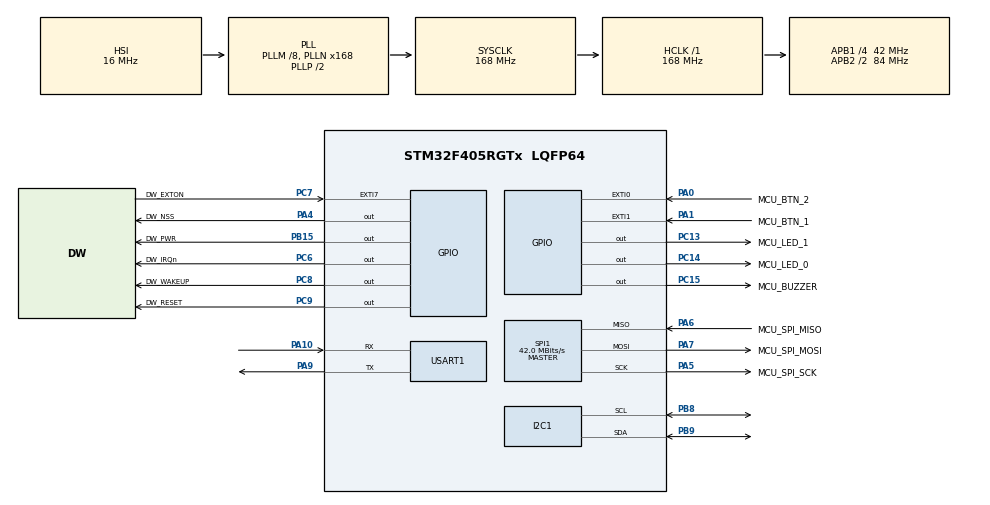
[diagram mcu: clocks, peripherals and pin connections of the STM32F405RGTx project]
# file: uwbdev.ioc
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I2C1.I2C_Mode=I2C_Fast
Mcu.Family=STM32F4
Mcu.Name=STM32F405RGTx
Mcu.Package=LQFP64
NVIC.EXTI0_IRQn=true\:0\:0\:false\:false\:true\:true\:true\:true
NVIC.EXTI1_IRQn=true\:0\:0\:false\:false\:true\:true\:true\:true
NVIC.EXTI9_5_IRQn=true\:0\:0\:false\:false\:true\:true\:true\:true
NVIC.PriorityGroup=NVIC_PRIORITYGROUP_4
PA0-WKUP.GPIO_Label=MCU_BTN_2
PA0-WKUP.GPIO_ModeDefaultEXTI=GPIO_MODE_IT_FALLING
PA0-WKUP.GPIO_PuPd=GPIO_PULLUP
PA0-WKUP.Signal=GPXTI0
PA1.GPIO_Label=MCU_BTN_1
PA1.GPIO_ModeDefaultEXTI=GPIO_MODE_IT_FALLING
PA1.GPIO_PuPd=GPIO_PULLUP
PA1.Signal=GPXTI1
PA10.Mode=Asynchronous
PA10.Signal=USART1_RX
PA13.Mode=Serial_Wire
PA13.Signal=SYS_JTMS-SWDIO
PA14.Mode=Serial_Wire
PA14.Signal=SYS_JTCK-SWCLK
PA4.GPIO_Label=DW_NSS
PA4.GPIO_Speed=GPIO_SPEED_FREQ_HIGH
PA4.Signal=GPIO_Output
PA5.GPIO_Label=MCU_SPI_SCK
PA5.Mode=Full_Duplex_Master
PA5.Signal=SPI1_SCK
PA6.GPIO_Label=MCU_SPI_MISO
PA6.Mode=Full_Duplex_Master
PA6.Signal=SPI1_MISO
PA7.GPIO_Label=MCU_SPI_MOSI
PA7.Mode=Full_Duplex_Master
PA7.Signal=SPI1_MOSI
PA9.Mode=Asynchronous
PA9.Signal=USART1_TX
PB15.GPIO_Label=DW_PWR
PB15.Signal=GPIO_Output
PB8.Mode=I2C
PB8.Signal=I2C1_SCL
PB9.Mode=I2C
PB9.Signal=I2C1_SDA
PC13-ANTI_TAMP.GPIO_Label=MCU_LED_1
PC13-ANTI_TAMP.Signal=GPIO_Output
PC14-OSC32_IN.GPIO_Label=MCU_LED_0
PC14-OSC32_IN.Signal=GPIO_Output
PC15-OSC32_OUT.GPIO_Label=MCU_BUZZER
PC15-OSC32_OUT.Signal=GPIO_Output
PC6.GPIO_Label=DW_IRQn
PC6.GPIO_Speed=GPIO_SPEED_FREQ_HIGH
PC6.PinState=GPIO_PIN_RESET
PC6.Signal=GPIO_Output
PC7.GPIO_Label=DW_EXTON
PC7.Signal=GPXTI7
PC8.GPIO_Label=DW_WAKEUP
PC8.GPIO_Speed=GPIO_SPEED_FREQ_HIGH
PC8.Signal=GPIO_Output
PC9.GPIO_Label=DW_RESET
PC9.GPIO_Speed=GPIO_SPEED_FREQ_HIGH
PC9.Signal=GPIO_Output
ProjectManager.HeapSize=0x200
ProjectManager.StackSize=0x400
ProjectManager.TargetToolchain=STM32CubeIDE
RCC.48MHZClocksFreq_Value=84000000
RCC.AHBFreq_Value=168000000
RCC.APB1CLKDivider=RCC_HCLK_DIV4
RCC.APB1Freq_Value=42000000
RCC.APB1TimFreq_Value=84000000
RCC.APB2CLKDivider=RCC_HCLK_DIV2
RCC.APB2Freq_Value=84000000
RCC.APB2TimFreq_Value=168000000
RCC.CortexFreq_Value=168000000
RCC.HCLKFreq_Value=168000000
RCC.HSE_VALUE=25000000
RCC.HSI_VALUE=16000000
RCC.LSE_VALUE=32768
RCC.PLLM=8
RCC.PLLN=168
RCC.SYSCLKFreq_VALUE=168000000
RCC.SYSCLKSource=RCC_SYSCLKSOURCE_PLLCLK
RCC.VCOOutputFreq_Value=336000000
SPI1.CalculateBaudRate=42.0 MBits/s
SPI1.Direction=SPI_DIRECTION_2LINES
SPI1.Mode=SPI_MODE_MASTER
SPI1.VirtualType=VM_MASTER
TIM5.Prescaler=167
USART1.VirtualMode=VM_ASYNC
VP_TIM5_VS_ClockSourceINT.Mode=Internal
board=custom

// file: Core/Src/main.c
/* USER CODE BEGIN Header */
/**
  ******************************************************************************
  * @file           : main.c
  * @brief          : Main program body
  ******************************************************************************
  * @attention
  *
  * Copyright (c) 2025 STMicroelectronics.
  * All rights reserved.
  *
  * This software is licensed under terms that can be found in the LICENSE file
  * in the root directory of this software component.
  * If no LICENSE file comes with this software, it is provided AS-IS.
  *
  ******************************************************************************
  */
/* USER CODE END Header */
#include "main.h"
#include "i2c.h"
#include "spi.h"
#include "tim.h"
#include "usart.h"
#include "gpio.h"

/* USER CODE BEGIN Includes */
#include "app_main.h"
#include "mode_anchor.h"
#include "mode_tag.h"
/* USER CODE END Includes */

/* USER CODE BEGIN PTD */
static uwb_anchor_t uwba;

/*Uwb Statics variable*/

/* USER CODE END PTD */

void SystemClock_Config(void);

int main(void)
{

  /* MCU Configuration--------------------------------------------------------*/

  /* Reset of all peripherals, Initializes the Flash interface and the Systick. */
  HAL_Init();

  /* Configure the system clock */
  SystemClock_Config();

  /* Initialize all configured peripherals */
  MX_GPIO_Init();
  MX_I2C1_Init();
  MX_SPI1_Init();
  MX_TIM5_Init();
  MX_USART1_UART_Init();
  /* USER CODE BEGIN 2 */
  app_init();
#if DEFAULT_MODE_SELECT == 0
	  uwb_mode_anchor_init(&uwba);
#elif DEFAULT_MODE_SELECT == 1

#endif

  /* USER CODE END 2 */

  /* Infinite loop */
  while (1)
  {
#if DEFAULT_MODE_SELECT == 0
	  mode_anchor_run(&uwba);
#elif DEFAULT_MODE_SELECT == 1
	  mode_tag_run();
#endif
  }
}

void SystemClock_Config(void)
{
  RCC_OscInitTypeDef RCC_OscInitStruct = {0};
  RCC_ClkInitTypeDef RCC_ClkInitStruct = {0};

  /** Configure the main internal regulator output voltage
  */
  __HAL_RCC_PWR_CLK_ENABLE();
  __HAL_PWR_VOLTAGESCALING_CONFIG(PWR_REGULATOR_VOLTAGE_SCALE1);

  /** Initializes the RCC Oscillators according to the specified parameters
  * in the RCC_OscInitTypeDef structure.
  */
  RCC_OscInitStruct.OscillatorType = RCC_OSCILLATORTYPE_HSI;
  RCC_OscInitStruct.HSIState = RCC_HSI_ON;
  RCC_OscInitStruct.HSICalibrationValue = RCC_HSICALIBRATION_DEFAULT;
  RCC_OscInitStruct.PLL.PLLState = RCC_PLL_ON;
  RCC_OscInitStruct.PLL.PLLSource = RCC_PLLSOURCE_HSI;
  RCC_OscInitStruct.PLL.PLLM = 8;
  RCC_OscInitStruct.PLL.PLLN = 168;
  RCC_OscInitStruct.PLL.PLLP = RCC_PLLP_DIV2;
  RCC_OscInitStruct.PLL.PLLQ = 4;
  if (HAL_RCC_OscConfig(&RCC_OscInitStruct) != HAL_OK)
  {
    Error_Handler();
  }

  /** Initializes the CPU, AHB and APB buses clocks
  */
  RCC_ClkInitStruct.ClockType = RCC_CLOCKTYPE_HCLK|RCC_CLOCKTYPE_SYSCLK
                              |RCC_CLOCKTYPE_PCLK1|RCC_CLOCKTYPE_PCLK2;
  RCC_ClkInitStruct.SYSCLKSource = RCC_SYSCLKSOURCE_PLLCLK;
  RCC_ClkInitStruct.AHBCLKDivider = RCC_SYSCLK_DIV1;
  RCC_ClkInitStruct.APB1CLKDivider = RCC_HCLK_DIV4;
  RCC_ClkInitStruct.APB2CLKDivider = RCC_HCLK_DIV2;

  if (HAL_RCC_ClockConfig(&RCC_ClkInitStruct, FLASH_LATENCY_5) != HAL_OK)
  {
    Error_Handler();
  }
}

void Error_Handler(void)
{
  __disable_irq();
  while (1)
  {
  }
}
